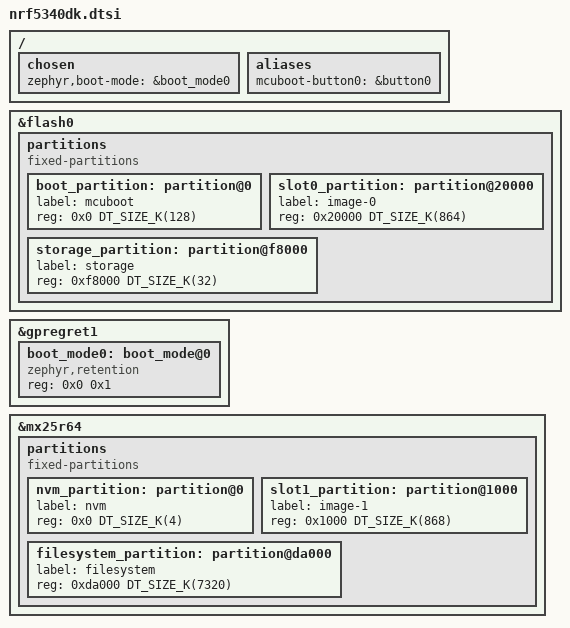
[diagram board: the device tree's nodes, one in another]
/* Delete Zephyr-default partitions before redefining them. */
&flash0 { /delete-node/ partitions; };

&gpregret1 {
	status = "okay";

	boot_mode0: boot_mode@0 {
		compatible = "zephyr,retention";
		status = "okay";
		reg = <0x0 0x1>;
	};
};

/ {
	chosen {
		zephyr,boot-mode = &boot_mode0;
	};

	aliases {
		mcuboot-button0 = &button0;
	};
};

&flash0 {
	partitions {
		compatible = "fixed-partitions";
		#address-cells = <1>;
		#size-cells = <1>;

		boot_partition: partition@0 {
			label = "mcuboot";
			reg = <0x0 DT_SIZE_K(128)>;
		};

		slot0_partition: partition@20000 {
			label = "image-0";
			reg = <0x20000 DT_SIZE_K(864)>;
		};

		storage_partition: partition@f8000 {
			label = "storage";
			reg = <0xf8000 DT_SIZE_K(32)>;
		};
	};
};

&mx25r64 {
	partitions {
		compatible = "fixed-partitions";
		#address-cells = <1>;
		#size-cells = <1>;

		nvm_partition: partition@0 {
			label = "nvm";
			reg = <0x0 DT_SIZE_K(4)>;
		};

		slot1_partition: partition@1000 {
			label = "image-1";
			reg = <0x1000 DT_SIZE_K(868)>;
		};

		filesystem_partition: partition@da000 {
			label = "filesystem";
			reg = <0xda000 DT_SIZE_K(7320)>;
		};
	};
};
